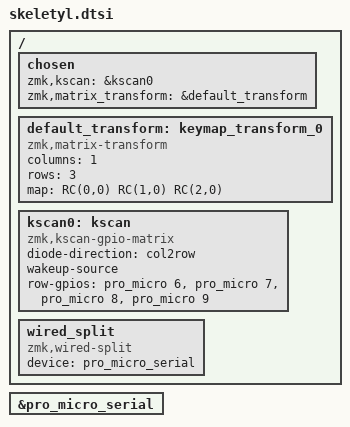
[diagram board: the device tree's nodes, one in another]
#include <dt-bindings/zmk/matrix_transform.h>

/ {
    chosen {
        zmk,kscan = &kscan0;
        zmk,matrix_transform = &default_transform;
    };

    default_transform: keymap_transform_0 {
        compatible = "zmk,matrix-transform";
        columns = <1>;
        rows = <3>;
        map = <
RC(0,0) 
RC(1,0) 
RC(2,0) 
        
        >;
    };

    kscan0: kscan {
        compatible = "zmk,kscan-gpio-matrix";
        diode-direction = "col2row";
        wakeup-source;
        
        row-gpios 
            = <&pro_micro 6 (GPIO_ACTIVE_HIGH | GPIO_PULL_DOWN)> 
            , <&pro_micro 7 (GPIO_ACTIVE_HIGH | GPIO_PULL_DOWN)> 
            , <&pro_micro 8 (GPIO_ACTIVE_HIGH | GPIO_PULL_DOWN)> 
            , <&pro_micro 9 (GPIO_ACTIVE_HIGH | GPIO_PULL_DOWN)> 
            ; 
    };
    
    wired_split {
        compatible = "zmk,wired-split";
        device = <&pro_micro_serial>;
    };
    
};

&pro_micro_serial {
    status = "okay";
};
